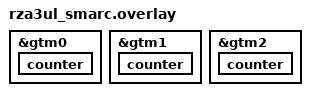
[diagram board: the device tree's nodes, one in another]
/*
 * Copyright (c) 2025 Renesas Electronics Corporation
 *
 * SPDX-License-Identifier: Apache-2.0
 */

&gtm0 {
	status = "okay";

	counter {
		status = "okay";
	};
};

&gtm1 {
	status = "okay";

	counter {
		status = "okay";
	};
};

&gtm2 {
	status = "okay";

	counter {
		status = "okay";
	};
};
